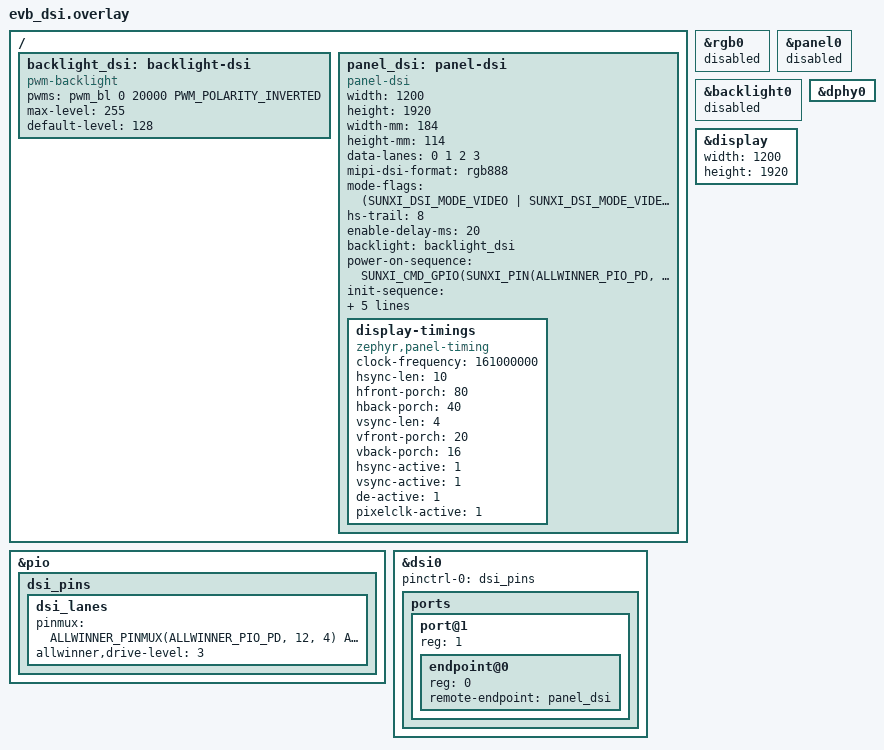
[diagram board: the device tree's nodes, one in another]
/*
 * 1200x1920 4-lane MIPI DSI panel instead of the RGB panel.
 * Build with -DEXTRA_DTC_OVERLAY_FILE=boards/evb_dsi.overlay
 *
 * Not tested on hardware.
 */
#include <zephyr/dt-bindings/display/sunxi-display.h>
#include <zephyr/dt-bindings/pwm/pwm.h>

&pio {
	dsi_pins: dsi_pins {
		dsi_lanes {
			pinmux = <ALLWINNER_PINMUX(ALLWINNER_PIO_PD, 12, 4)
				  ALLWINNER_PINMUX(ALLWINNER_PIO_PD, 13, 4)
				  ALLWINNER_PINMUX(ALLWINNER_PIO_PD, 14, 4)
				  ALLWINNER_PINMUX(ALLWINNER_PIO_PD, 15, 4)
				  ALLWINNER_PINMUX(ALLWINNER_PIO_PD, 16, 4)
				  ALLWINNER_PINMUX(ALLWINNER_PIO_PD, 17, 4)
				  ALLWINNER_PINMUX(ALLWINNER_PIO_PD, 18, 4)
				  ALLWINNER_PINMUX(ALLWINNER_PIO_PD, 19, 4)
				  ALLWINNER_PINMUX(ALLWINNER_PIO_PD, 20, 4)
				  ALLWINNER_PINMUX(ALLWINNER_PIO_PD, 21, 4)>;
			allwinner,drive-level = <3>;
		};
	};
};

/ {
	backlight_dsi: backlight-dsi {
		compatible = "pwm-backlight";
		pwms = <&pwm_bl 0 20000 PWM_POLARITY_INVERTED>;
		max-level = <255>;
		default-level = <128>;
	};

	panel_dsi: panel-dsi {
		compatible = "panel-dsi";
		width = <1200>;
		height = <1920>;
		width-mm = <184>;
		height-mm = <114>;
		data-lanes = <0 1 2 3>;
		mipi-dsi-format = "rgb888";
		mode-flags = <(SUNXI_DSI_MODE_VIDEO | SUNXI_DSI_MODE_VIDEO_SYNC_PULSE |
			       SUNXI_DSI_MODE_LPM)>;
		hs-trail = <8>;
		enable-delay-ms = <20>;
		backlight = <&backlight_dsi>;

		/* PD22 = panel supply, PD9 = reset */
		power-on-sequence = <SUNXI_CMD_GPIO(SUNXI_PIN(ALLWINNER_PIO_PD, 22), 1)
				     SUNXI_CMD_DELAY(10)
				     SUNXI_CMD_GPIO(SUNXI_PIN(ALLWINNER_PIO_PD, 9), 1)
				     SUNXI_CMD_DELAY(100)
				     SUNXI_CMD_GPIO(SUNXI_PIN(ALLWINNER_PIO_PD, 9), 0)
				     SUNXI_CMD_DELAY(100)
				     SUNXI_CMD_GPIO(SUNXI_PIN(ALLWINNER_PIO_PD, 9), 1)
				     SUNXI_CMD_DELAY(100)>;
		init-sequence = <SUNXI_CMD_DCS(120, 1, 0x11)	/* exit sleep */
				 SUNXI_CMD_DCS(20, 1, 0x29)>;	/* display on */
		exit-sequence = <SUNXI_CMD_DCS(0, 1, 0x28)		/* display off */
				 SUNXI_CMD_DCS(120, 1, 0x10)>;	/* enter sleep */
		power-off-sequence = <SUNXI_CMD_GPIO(SUNXI_PIN(ALLWINNER_PIO_PD, 9), 0)
				      SUNXI_CMD_DELAY(5)
				      SUNXI_CMD_GPIO(SUNXI_PIN(ALLWINNER_PIO_PD, 22), 0)>;

		display-timings {
			compatible = "zephyr,panel-timing";
			clock-frequency = <161000000>;
			hsync-len = <10>;
			hfront-porch = <80>;
			hback-porch = <40>;
			vsync-len = <4>;
			vfront-porch = <20>;
			vback-porch = <16>;
			hsync-active = <1>;
			vsync-active = <1>;
			de-active = <1>;
			pixelclk-active = <1>;
		};
	};
};

/* the RGB panel shares the LCD pins */
&rgb0 {
	status = "disabled";
};

&panel0 {
	status = "disabled";
};

&backlight0 {
	status = "disabled";
};

&dphy0 {
	status = "okay";
};

&dsi0 {
	status = "okay";
	pinctrl-0 = <&dsi_pins>;
	pinctrl-names = "default";

	ports {
		#address-cells = <1>;
		#size-cells = <0>;

		port@1 {
			reg = <1>;
			#address-cells = <1>;
			#size-cells = <0>;

			endpoint@0 {
				reg = <0>;
				remote-endpoint = <&panel_dsi>;
			};
		};
	};
};

&display {
	width = <1200>;
	height = <1920>;
};
